# ESP32-C6 register map
Vendor: ESPRESSIF SYSTEMS (SHANGHAI) CO., LTD.; Series: ESP32 C-Series; File version: 5
CPU: RV32IMAC r0p0, little endian, no MPU, no FPU, 4 interrupt priority bits
Address unit: 32 bits
Registers are 32-bit, read-write, reset 0x0 unless marked. A register's access mark holds for its fields unless they carry their own. Offsets are from the block's base; [hi:lo] are bit positions; {n}, {i} and the like mark numbered series.

## LP_CLKRST — LP_CLKRST Peripheral
Base 0x600B0400
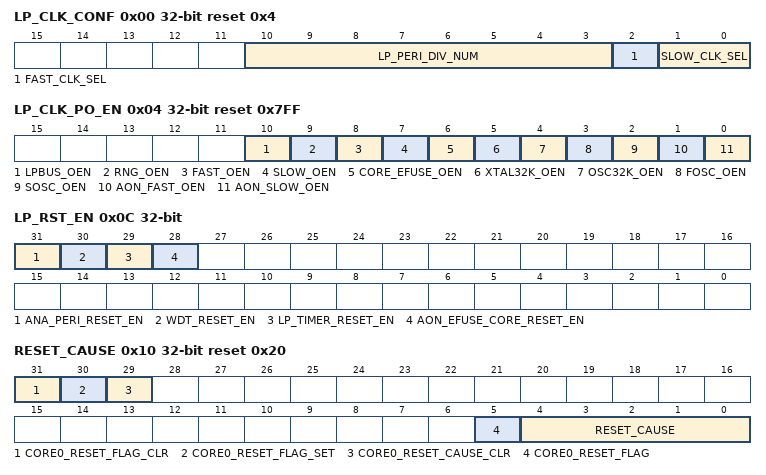
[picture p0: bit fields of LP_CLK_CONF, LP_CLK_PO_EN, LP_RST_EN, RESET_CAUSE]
0x00 LP_CLK_CONF reset 0x4 — need_des
  [10:3] LP_PERI_DIV_NUM — need_des
  [2] FAST_CLK_SEL — need_des
  [1:0] SLOW_CLK_SEL — need_des
0x04 LP_CLK_PO_EN reset 0x7FF — need_des
  [10] LPBUS_OEN — need_des
  [9] RNG_OEN — need_des
  [8] FAST_OEN — need_des
  [7] SLOW_OEN — need_des
  [6] CORE_EFUSE_OEN — need_des
  [5] XTAL32K_OEN — need_des
  [4] OSC32K_OEN — need_des
  [3] FOSC_OEN — need_des
  [2] SOSC_OEN — need_des
  [1] AON_FAST_OEN — need_des
  [0] AON_SLOW_OEN — need_des
0x08 LP_CLK_EN — need_des
  [31] FAST_ORI_GATE
0x0C LP_RST_EN — need_des
  [31] ANA_PERI_RESET_EN — need_des
  [30] WDT_RESET_EN — need_des
  [29] LP_TIMER_RESET_EN — need_des
  [28] AON_EFUSE_CORE_RESET_EN — need_des
0x10 RESET_CAUSE access per field reset 0x20 — need_des
  [31] CORE0_RESET_FLAG_CLR wo — need_des
  [30] CORE0_RESET_FLAG_SET wo — need_des
  [29] CORE0_RESET_CAUSE_CLR wo — need_des
  [5] CORE0_RESET_FLAG ro — need_des
  [4:0] RESET_CAUSE ro — need_des
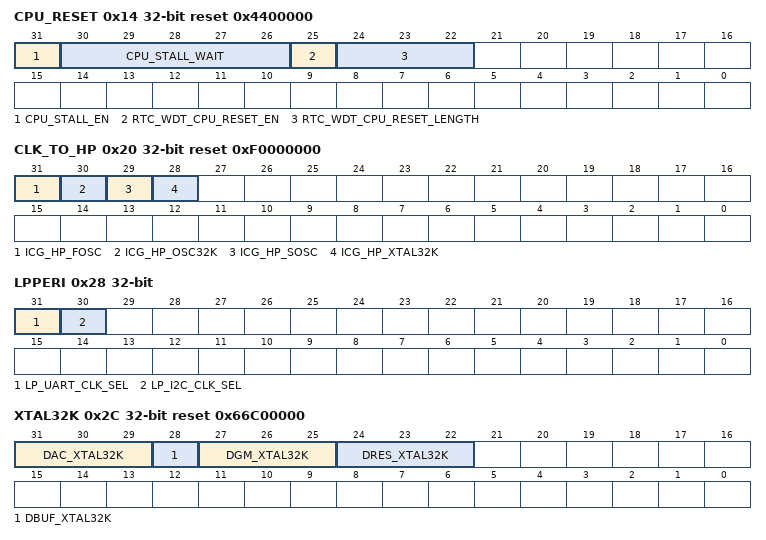
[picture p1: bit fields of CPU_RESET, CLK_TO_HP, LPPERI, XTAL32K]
0x14 CPU_RESET reset 0x4400000 — need_des
  [31] CPU_STALL_EN — need_des
  [30:26] CPU_STALL_WAIT — need_des
  [25] RTC_WDT_CPU_RESET_EN — need_des
  [24:22] RTC_WDT_CPU_RESET_LENGTH — need_des
0x18 FOSC_CNTL reset 0x2B000000 — need_des
  [31:22] FOSC_DFREQ
0x1C RC32K_CNTL reset 0x2B000000 — need_des
  [31:22] RC32K_DFREQ
0x20 CLK_TO_HP reset 0xF0000000 — need_des
  [31] ICG_HP_FOSC — need_des
  [30] ICG_HP_OSC32K — need_des
  [29] ICG_HP_SOSC — need_des
  [28] ICG_HP_XTAL32K — need_des
0x24 LPMEM_FORCE — need_des
  [31] LPMEM_CLK_FORCE_ON
0x28 LPPERI — need_des
  [31] LP_UART_CLK_SEL — need_des
  [30] LP_I2C_CLK_SEL — need_des
0x2C XTAL32K reset 0x66C00000 — need_des
  [31:29] DAC_XTAL32K — need_des
  [28] DBUF_XTAL32K — need_des
  [27:25] DGM_XTAL32K — need_des
  [24:22] DRES_XTAL32K — need_des
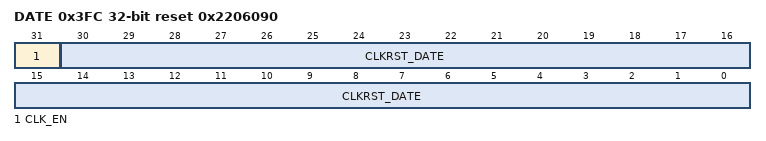
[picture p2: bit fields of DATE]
0x3FC DATE reset 0x2206090 — need_des
  [31] CLK_EN — need_des
  [30:0] CLKRST_DATE — need_des

## LP_I2C_ANA_MST — LP_I2C_ANA_MST Peripheral
Base 0x600B2400
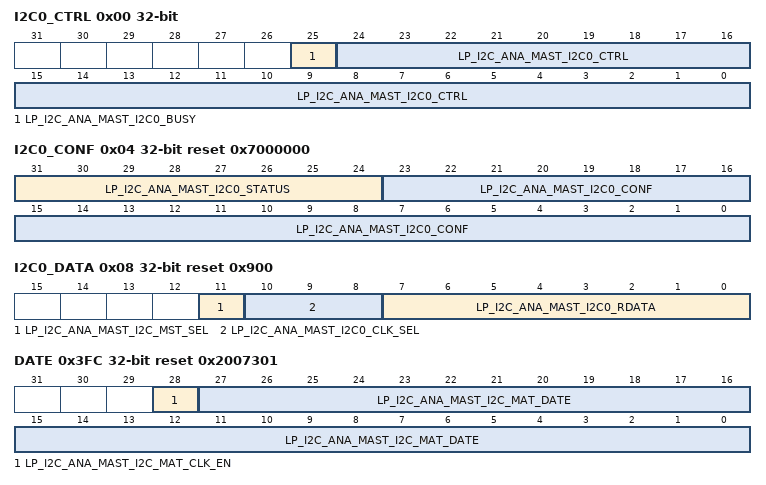
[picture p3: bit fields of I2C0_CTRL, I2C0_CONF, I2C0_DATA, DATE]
0x00 I2C0_CTRL access per field — need_des
  [25] LP_I2C_ANA_MAST_I2C0_BUSY ro — need_des
  [24:0] LP_I2C_ANA_MAST_I2C0_CTRL rw — need_des
0x04 I2C0_CONF access per field reset 0x7000000 — need_des
  [31:24] LP_I2C_ANA_MAST_I2C0_STATUS ro — reserved
  [23:0] LP_I2C_ANA_MAST_I2C0_CONF rw — need_des
0x08 I2C0_DATA access per field reset 0x900 — need_des
  [11] LP_I2C_ANA_MAST_I2C_MST_SEL rw — need des
  [10:8] LP_I2C_ANA_MAST_I2C0_CLK_SEL rw — need_des
  [7:0] LP_I2C_ANA_MAST_I2C0_RDATA ro — need_des
0x0C ANA_CONF1 — need_des
  [23:0] LP_I2C_ANA_MAST_ANA_CONF1
0x10 NOUSE — need_des
  [31:0] LP_I2C_ANA_MAST_I2C_MST_NOUSE
0x14 DEVICE_EN — need_des
  [11:0] LP_I2C_ANA_MAST_I2C_DEVICE_EN
0x3FC DATE reset 0x2007301 — need_des
  [28] LP_I2C_ANA_MAST_I2C_MAT_CLK_EN — need_des
  [27:0] LP_I2C_ANA_MAST_I2C_MAT_DATE — need_des

## LP_IO — LP_IO Peripheral
Base 0x600B2000
0x00 OUT_DATA — need des
  [7:0] LP_GPIO_OUT_DATA — set lp gpio output data
0x04 OUT_DATA_W1TS wo — need des
  [7:0] LP_GPIO_OUT_DATA_W1TS — set one time output data
0x08 OUT_DATA_W1TC wo — need des
  [7:0] LP_GPIO_OUT_DATA_W1TC — clear one time output data
0x0C OUT_ENABLE — need des
  [7:0] LP_GPIO_ENABLE — set lp gpio output data
0x10 OUT_ENABLE_W1TS wo — need des
  [7:0] LP_GPIO_ENABLE_W1TS — set one time output data
0x14 OUT_ENABLE_W1TC wo — need des
  [7:0] LP_GPIO_ENABLE_W1TC — clear one time output data
0x18 STATUS — need des
  [7:0] LP_GPIO_STATUS_INTERRUPT — set lp gpio output data
0x1C STATUS_W1TS wo — need des
  [7:0] LP_GPIO_STATUS_W1TS — set one time output data
0x20 STATUS_W1TC wo — need des
  [7:0] LP_GPIO_STATUS_W1TC — clear one time output data
0x24 IN ro — need des
  [7:0] LP_GPIO_IN_DATA_NEXT
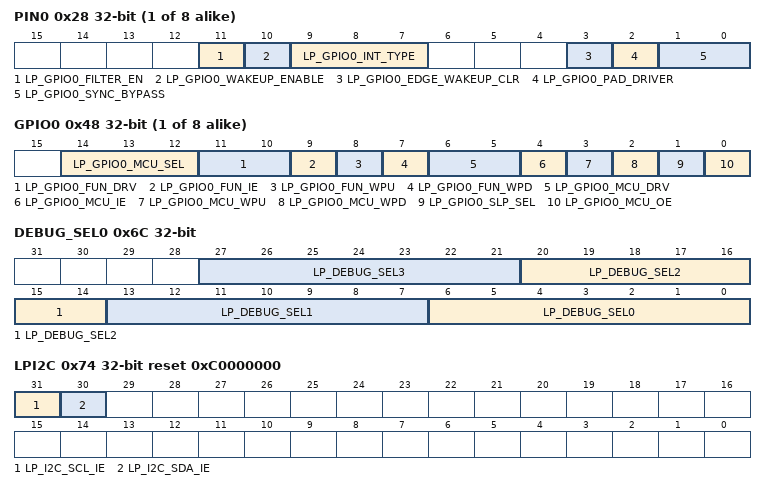
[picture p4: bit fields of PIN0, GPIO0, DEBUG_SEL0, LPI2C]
{0x28+4i} PIN{i} access per field (i=0..7) — need des
  [11] LP_GPIO{i}_FILTER_EN rw — need des
  [10] LP_GPIO{i}_WAKEUP_ENABLE rw — need des
  [9:7] LP_GPIO{i}_INT_TYPE rw — need des
  [3] LP_GPIO{i}_EDGE_WAKEUP_CLR wo — need des
  [2] LP_GPIO{i}_PAD_DRIVER rw — need des
  [1:0] LP_GPIO{i}_SYNC_BYPASS rw — need des
{0x48+4i} GPIO{i} (i=0..7) — need des
  [14:12] LP_GPIO{i}_MCU_SEL — need des
  [11:10] LP_GPIO{i}_FUN_DRV — need des
  [9] LP_GPIO{i}_FUN_IE — need des
  [8] LP_GPIO{i}_FUN_WPU — need des
  [7] LP_GPIO{i}_FUN_WPD — need des
  [6:5] LP_GPIO{i}_MCU_DRV — need des
  [4] LP_GPIO{i}_MCU_IE — need des
  [3] LP_GPIO{i}_MCU_WPU — need des
  [2] LP_GPIO{i}_MCU_WPD — need des
  [1] LP_GPIO{i}_SLP_SEL — need des
  [0] LP_GPIO{i}_MCU_OE — need des
0x68 STATUS_INTERRUPT ro — need des
  [7:0] LP_GPIO_STATUS_INTERRUPT_NEXT
0x6C DEBUG_SEL0 — need des
  [7n+6:7n] LP_DEBUG_SEL{n} (n=0..3) — need des
0x70 DEBUG_SEL1 — need des
  [6:0] LP_DEBUG_SEL4
0x74 LPI2C reset 0xC0000000 — need des
  [31] LP_I2C_SCL_IE — need des
  [30] LP_I2C_SDA_IE — need des
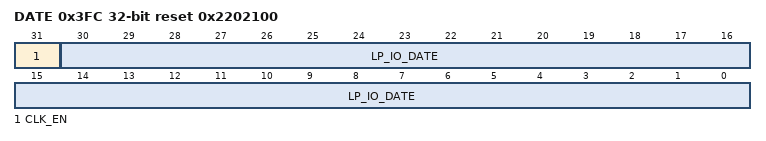
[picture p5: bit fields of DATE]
0x3FC DATE reset 0x2202100 — need des
  [31] CLK_EN — need des
  [30:0] LP_IO_DATE — need des
